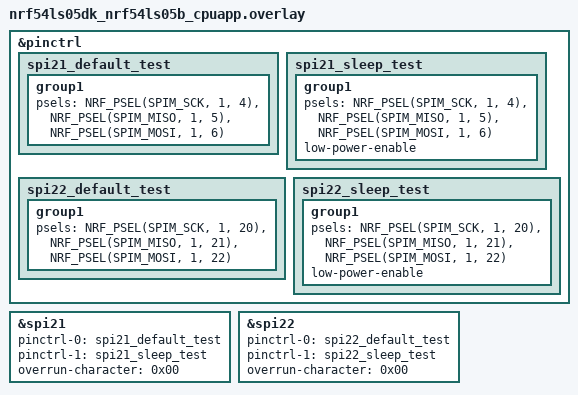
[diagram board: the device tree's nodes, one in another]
/*
 * Copyright (c) 2025 Nordic Semiconductor ASA
 *
 * SPDX-License-Identifier: LicenseRef-Nordic-5-Clause
 */

&pinctrl {
	spi21_default_test: spi21_default_test {
		group1 {
			psels = <NRF_PSEL(SPIM_SCK, 1, 4)>,
				<NRF_PSEL(SPIM_MISO, 1, 5)>,
				<NRF_PSEL(SPIM_MOSI, 1, 6)>;
		};
	};

	spi21_sleep_test: spi21_sleep_test {
		group1 {
			psels = <NRF_PSEL(SPIM_SCK, 1, 4)>,
				<NRF_PSEL(SPIM_MISO, 1, 5)>,
				<NRF_PSEL(SPIM_MOSI, 1, 6)>;
			low-power-enable;
		};
	};

	spi22_default_test: spi22_default_test {
		group1 {
			psels = <NRF_PSEL(SPIM_SCK, 1, 20)>,
				<NRF_PSEL(SPIM_MISO, 1, 21)>,
				<NRF_PSEL(SPIM_MOSI, 1, 22)>;
		};
	};

	spi22_sleep_test: spi22_sleep_test {
		group1 {
			psels = <NRF_PSEL(SPIM_SCK, 1, 20)>,
				<NRF_PSEL(SPIM_MISO, 1, 21)>,
				<NRF_PSEL(SPIM_MOSI, 1, 22)>;
			low-power-enable;
		};
	};
};

/* spi20 inaccessible due to console on uart20 */

&spi21 {
	status = "okay";
	pinctrl-0 = <&spi21_default_test>;
	pinctrl-1 = <&spi21_sleep_test>;
	pinctrl-names = "default", "sleep";
	overrun-character = <0x00>;
};

&spi22 {
	status = "okay";
	pinctrl-0 = <&spi22_default_test>;
	pinctrl-1 = <&spi22_sleep_test>;
	pinctrl-names = "default", "sleep";
	overrun-character = <0x00>;
};
